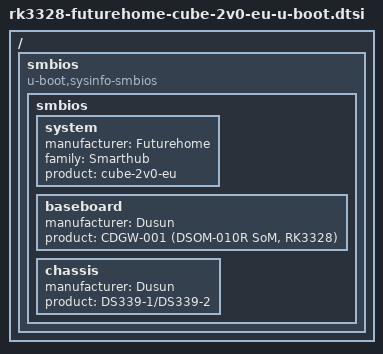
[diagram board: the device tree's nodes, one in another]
// SPDX-License-Identifier: GPL-2.0+
#include "rk3328-u-boot.dtsi"
#include "rk3328-sdram-ddr3-666.dtsi"
/ {
    smbios {
		compatible = "u-boot,sysinfo-smbios";
		
        smbios {
			system {
				manufacturer = "Futurehome";
                family = "Smarthub";
				product = "cube-2v0-eu";
			};

			baseboard {
				manufacturer = "Dusun";
				product = "CDGW-001 (DSOM-010R SoM, RK3328)";
			};

			chassis {
				manufacturer = "Dusun";
				product = "DS339-1/DS339-2";
			};
		};
	};
};
